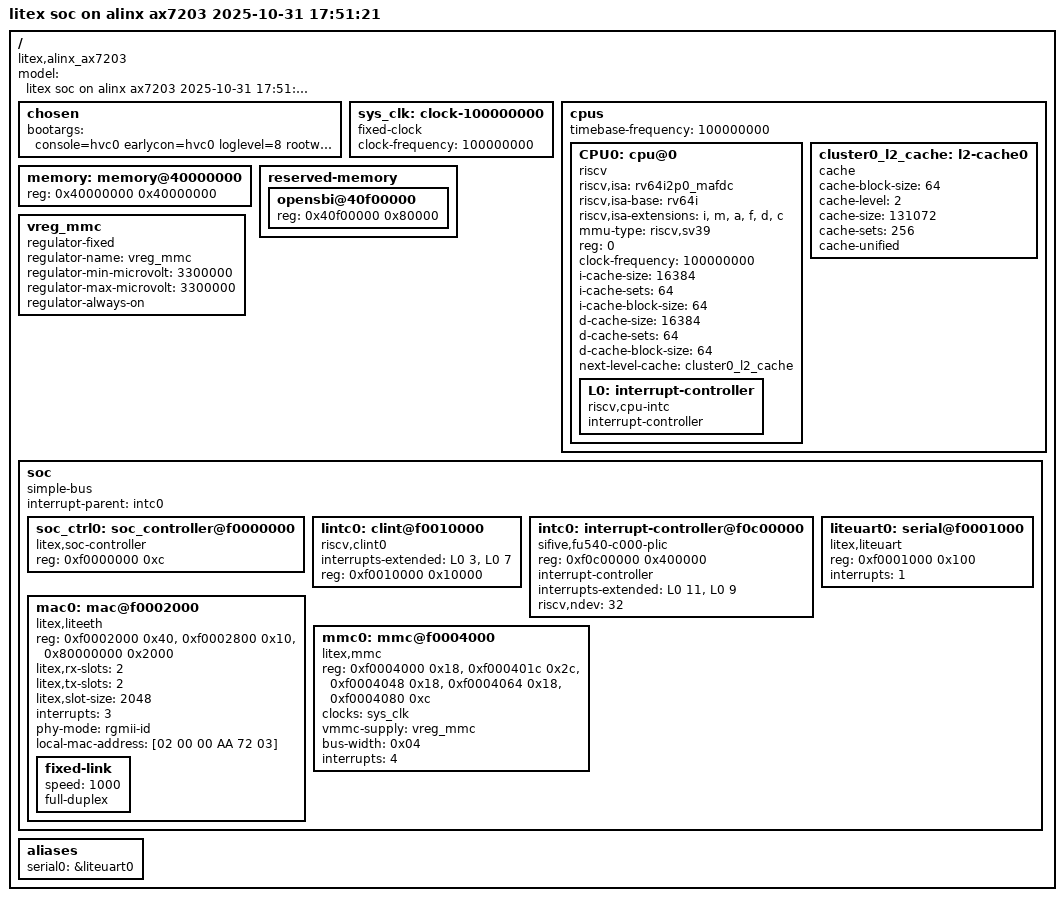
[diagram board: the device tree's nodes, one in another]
/dts-v1/;

/ {
	compatible = "litex,alinx_ax7203", "litex,soc";
	model = "litex soc on alinx ax7203 2025-10-31 17:51:21";
	#address-cells = <1>;
	#size-cells    = <1>;

	chosen {
		bootargs = "console=hvc0 earlycon=hvc0 loglevel=8 rootwait root=/dev/mmcblk0p2";
	};

	sys_clk: clock-100000000 {
		compatible = "fixed-clock";
		#clock-cells = <0>;
		clock-frequency  = <100000000>;
	};

	cpus {
		#address-cells = <1>;
		#size-cells    = <0>;
		timebase-frequency = <100000000>;
		CPU0: cpu@0 {
			device_type = "cpu";
			compatible = "riscv";
			riscv,isa = "rv64i2p0_mafdc";
			riscv,isa-base = "rv64i";
			riscv,isa-extensions = "i", "m", "a", "f", "d", "c";
			mmu-type = "riscv,sv39";
			reg = <0>;
			clock-frequency = <100000000>;
			status = "okay";
			i-cache-size = <16384>;
			i-cache-sets = <64>;
			i-cache-block-size = <64>;
			d-cache-size = <16384>;
			d-cache-sets = <64>;
			d-cache-block-size = <64>;
			next-level-cache = <&cluster0_l2_cache>;
			L0: interrupt-controller {
				#address-cells = <0>;
				#interrupt-cells = <1>;
				interrupt-controller;
				compatible = "riscv,cpu-intc";
			};
		};
		cluster0_l2_cache: l2-cache0 {
			compatible = "cache";
			cache-block-size = <64>;
			cache-level = <2>;
			cache-size = <131072>;
			cache-sets = <256>;
			cache-unified;
		};
	};

	memory: memory@40000000 {
		device_type = "memory";
		reg = <0x40000000 0x40000000>;
	};

	reserved-memory {
		#address-cells = <1>;
		#size-cells    = <1>;
		ranges;
		opensbi@40f00000 {
			reg = <0x40f00000 0x80000>;
		};
	};

	vreg_mmc: vreg_mmc {
		compatible = "regulator-fixed";
		regulator-name = "vreg_mmc";
		regulator-min-microvolt = <3300000>;
		regulator-max-microvolt = <3300000>;
		regulator-always-on;
	};

	soc {
		#address-cells = <1>;
		#size-cells    = <1>;
		compatible = "simple-bus";
		interrupt-parent = <&intc0>;
		ranges;

		soc_ctrl0: soc_controller@f0000000 {
			compatible = "litex,soc-controller";
			reg = <0xf0000000 0xc>;
			status = "okay";
		};

		lintc0: clint@f0010000 {
			compatible = "riscv,clint0";
			interrupts-extended =
				<&L0 3 &L0 7>;
			reg = <0xf0010000 0x10000>;
			reg-names = "control";
		};
		intc0: interrupt-controller@f0c00000 {
			compatible = "sifive,fu540-c000-plic", "sifive,plic-1.0.0";
			reg = <0xf0c00000 0x400000>;
			#address-cells = <0>;
			#interrupt-cells = <1>;
			interrupt-controller;
			interrupts-extended =
				<&L0 11 &L0 9>;
			riscv,ndev = <32>;
		};

		liteuart0: serial@f0001000 {
			compatible = "litex,liteuart";
			reg = <0xf0001000 0x100>;
			interrupts = <1>;
			status = "okay";
		};

	mac0: mac@f0002000 {
		compatible = "litex,liteeth";
		reg = <0xf0002000 0x40>,
		      <0xf0002800 0x10>,
		      <0x80000000 0x2000>;
		reg-names = "mac", "mdio", "buffer";
		litex,rx-slots = <2>;
		litex,tx-slots = <2>;
		litex,slot-size = <2048>;
		interrupts = <3>;
		status = "okay";

		phy-mode = "rgmii-id";
		local-mac-address = [02 00 00 AA 72 03];

		fixed-link {
			speed = <1000>;
			full-duplex;
		};
	};

		mmc0: mmc@f0004000 {
			compatible = "litex,mmc";
			reg = <0xf0004000 0x18>,
			      <0xf000401c 0x2c>,
			      <0xf0004048 0x18>,
			      <0xf0004064 0x18>,
			      <0xf0004080 0xc>;
			reg-names = "phy", "core", "reader", "writer", "irq";
			clocks = <&sys_clk>;
			vmmc-supply = <&vreg_mmc>;
			bus-width = <0x04>;
			interrupts = <4>;
			status = "okay";
		};
	};

	aliases {
		serial0 = &liteuart0;
	};
};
